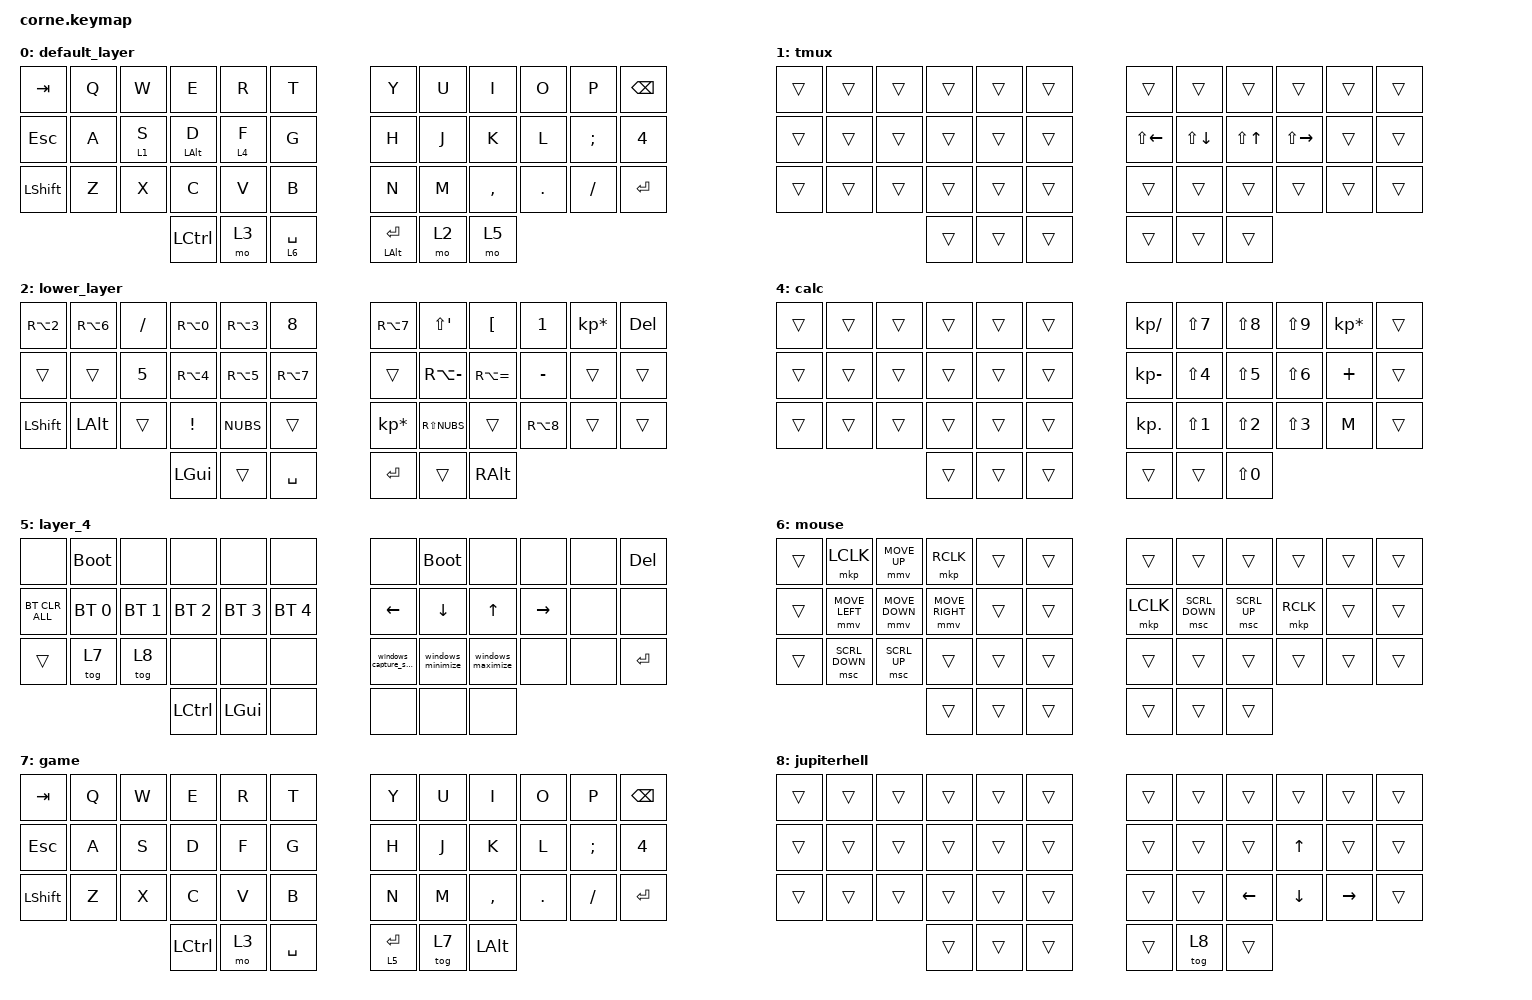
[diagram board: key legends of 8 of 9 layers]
/*
 * Copyright (c) 2020 The ZMK Contributors
 *
 * SPDX-License-Identifier: MIT
 */

#define ZMK_MOUSE_DEFAULT_MOVE_VAL 4000

#include <behaviors/mouse_keys.dtsi>
#include <dt-bindings/zmk/mouse.h>
#include <behaviors.dtsi>
#include <dt-bindings/zmk/bt.h>
#include <dt-bindings/zmk/keys.h>

#undef MOVE_UP
#undef MOVE_DOWN
#undef MOVE_LEFT
#undef MOVE_RIGHT

#define MOVE_UP MOVE_Y(-ZMK_MOUSE_DEFAULT_MOVE_VAL)
#define MOVE_DOWN MOVE_Y(ZMK_MOUSE_DEFAULT_MOVE_VAL)
#define MOVE_LEFT MOVE_X(-ZMK_MOUSE_DEFAULT_MOVE_VAL)
#define MOVE_RIGHT MOVE_X(ZMK_MOUSE_DEFAULT_MOVE_VAL)

&msc {
    time-to-max-speed-ms = <800>;             /* <--- How long time until max speed is reached (default: 500) */
};

/ {
    macros {
        macro_greater_than: macro_greater_than {
            compatible = "zmk,behavior-macro";
            #binding-cells = <0>;
            bindings =
                <&macro_press>,
                <&kp LEFT_ALT>,
                <&macro_tap>,
                <&kp KP_NUMBER_6 &kp KP_N2>,
                <&macro_release>,
                <&kp LEFT_ALT>;

            label = "MACRO_GREATER_THAN";
        };

        macro_less_than: macro_less_than {
            compatible = "zmk,behavior-macro";
            #binding-cells = <0>;
            bindings =
                <&macro_press>,
                <&kp LEFT_ALT>,
                <&macro_tap>,
                <&kp KP_NUMBER_6 &kp KP_N0>,
                <&macro_release>,
                <&kp LEFT_ALT>;

            label = "MACRO_LESS_THAN";
        };

        windows_capture_screen: windows_capture_screen {
            compatible = "zmk,behavior-macro";
            #binding-cells = <0>;
            bindings =
                <&macro_press>,
                <&kp LEFT_GUI>,
                <&macro_tap>,
                <&kp LS(S)>,
                <&macro_release>,
                <&kp LGUI>;

            label = "WINDOWS_CAPTURE_SCREEN";
        };

        windows_maximize: windows_fullscreen {
            compatible = "zmk,behavior-macro";
            #binding-cells = <0>;
            bindings =
                <&macro_press>,
                <&kp LEFT_GUI>,
                <&macro_tap>,
                <&kp UP_ARROW>,
                <&macro_release>,
                <&kp LGUI>;

            label = "WINDOWS_FULLSCREEN";
        };

        windows_minimize: windows_minimize {
            compatible = "zmk,behavior-macro";
            #binding-cells = <0>;
            bindings =
                <&macro_press>,
                <&kp LEFT_GUI>,
                <&macro_tap>,
                <&kp DOWN>,
                <&macro_release>,
                <&kp LEFT_GUI>;

            label = "WINDOWS_MINIMIZE";
        };
    };

    behaviors {
        homerow_alt: homerow_alt {
            compatible = "zmk,behavior-hold-tap";
            label = "HOMEROW_ALT";
            bindings = <&kp>, <&kp>;

            #binding-cells = <2>;
            flavor = "tap-preferred";
            tapping-term-ms = <170>;
            quick-tap-ms = <150>;
            require-prior-idle-ms = <0>;
            hold-trigger-key-positions = <14 15 16 19 20 21 22 18>;
        };

        mouse: mouse {
            compatible = "zmk,behavior-hold-tap";
            label = "MOUSE";
            bindings = <&mo>, <&kp>;

            #binding-cells = <2>;
            flavor = "tap-preferred";
            tapping-term-ms = <170>;
            quick-tap-ms = <150>;
            require-prior-idle-ms = <0>;
            hold-trigger-key-positions = <2 14 13 15 1 3>;
        };
    };

    keymap {
        compatible = "zmk,keymap";

        default_layer {
            // -----------------------------------------------------------------------------------------
            // |  TAB |  Q  |  W  |  E  |  R  |  T  |   |  Y  |  U   |  I  |  O  |  P  | BKSP |
            // | CTRL |  A  |  S  |  D  |  F  |  G  |   |  H  |  J   |  K  |  L  |  ;  |  '   |
            // | SHFT |  Z  |  X  |  C  |  V  |  B  |   |  N  |  M   |  ,  |  .  |  /  | ESC  |
            //                    | GUI | LWR | SPC |   | ENT | RSE  | ALT |

            bindings = <
&kp TAB     &kp Q  &kp W    &kp E                    &kp R    &kp T             &kp Y               &kp U  &kp I      &kp O    &kp P     &kp BSPC
&kp ESCAPE  &kp A  &lt 1 S  &homerow_alt LEFT_ALT D  &lt 4 F  &kp G             &kp H               &kp J  &kp K      &kp L    &kp SEMI  &kp NUMBER_4
&kp LSHFT   &kp Z  &kp X    &kp C                    &kp V    &kp B             &kp N               &kp M  &kp COMMA  &kp DOT  &kp FSLH  &kp ENTER
                            &kp LEFT_CONTROL         &mo 3    &mouse 6 SPACE    &mt LEFT_ALT ENTER  &mo 2  &mo 5
            >;
        };

        tmux {
            bindings = <
&trans  &trans  &trans  &trans  &trans  &trans    &trans        &trans        &trans            &trans         &trans  &trans
&trans  &trans  &trans  &trans  &trans  &trans    &kp LS(LEFT)  &kp LS(DOWN)  &kp LS(UP_ARROW)  &kp LS(RIGHT)  &trans  &trans
&trans  &trans  &trans  &trans  &trans  &trans    &trans        &trans        &trans            &trans         &trans  &trans
                        &trans  &trans  &trans    &trans        &trans        &trans
            >;
        };

        lower_layer {
            // -----------------------------------------------------------------------------------------
            // |  TAB |  1  |  2  |  3  |  4  |  5  |   |  6  |  7  |  8  |  9  |  0  | BKSP |
            // | BTCLR| BT1 | BT2 | BT3 | BT4 | BT5 |   | LFT | DWN |  UP | RGT |     |      |
            // | SHFT |     |     |     |     |     |   |     |     |     |     |     |      |
            //                    | GUI |     | SPC |   | ENT |     | ALT |

            bindings = <
&kp RA(NUMBER_2)  &kp RA(NUMBER_6)  &kp SLASH  &kp RA(N0)        &kp RA(NUMBER_3)  &kp N8        &kp RA(N7)       &kp LS(SQT)    &kp LEFT_BRACKET  &kp NUMBER_1  &kp KP_MULTIPLY  &kp DELETE
&trans            &trans            &kp N5     &kp RA(NUMBER_4)  &kp RA(N5)        &kp RA(N7)    &trans           &kp RA(MINUS)  &kp RA(EQUAL)     &kp MINUS     &trans           &trans
&kp LSHFT         &kp LEFT_ALT      &trans     &kp EXCLAMATION   &kp NUBS          &trans        &kp KP_MULTIPLY  &kp RS(NUBS)   &trans            &kp RA(N8)    &trans           &trans
                                               &kp LGUI          &trans            &kp SPACE     &kp RET          &trans         &kp RALT
            >;
        };

        raise_layer {
            // -----------------------------------------------------------------------------------------
            // |  TAB |  !  |  @  |  #  |  $  |  %  |   |  ^  |  &  |  *  |  (  |  )  | BKSP |
            // | CTRL |     |     |     |     |     |   |  -  |  =  |  [  |  ]  |  \  |  `   |
            // | SHFT |     |     |     |     |     |   |  _  |  +  |  {  |  }  | "|" |  ~   |
            //                    | GUI |     | SPC |   | ENT |     | ALT |

            bindings = <
&kp GRAVE  &kp NUMBER_1  &kp NUMBER_2  &kp NUMBER_3  &kp NUMBER_4  &kp N5     &kp NUMBER_6  &kp N7     &kp N8     &kp N9            &kp N0             &kp BSPC
&trans     &kp F1        &kp F2        &kp F3        &kp F4        &kp F5     &kp F6        &kp MINUS  &kp EQUAL  &kp LEFT_BRACKET  &kp RIGHT_BRACKET  &kp SQT
&trans     &kp F7        &kp F8        &kp F9        &kp F10       &kp F11    &kp F12       &kp NUHS   &kp NUBS   &trans            &trans             &kp TILDE
            >;
        };

        calc {
            bindings = <
&trans  &trans  &trans  &trans  &trans  &trans    &kp KP_DIVIDE  &kp LS(N7)        &kp LS(NUMBER_8)  &kp LS(N9)        &kp KP_ASTERISK  &trans
&trans  &trans  &trans  &trans  &trans  &trans    &kp KP_MINUS   &kp LS(NUMBER_4)  &kp LS(NUMBER_5)  &kp LS(NUMBER_6)  &kp PLUS         &trans
&trans  &trans  &trans  &trans  &trans  &trans    &kp KP_DOT     &kp LS(NUMBER_1)  &kp LS(NUMBER_2)  &kp LS(NUMBER_3)  &kp M            &trans
                        &trans  &trans  &trans    &trans         &trans            &kp LS(NUMBER_0)
            >;
        };

        layer_4 {
            bindings = <
&none           &bootloader   &none         &none         &none         &none           &none                    &bootloader        &none              &none      &none  &kp DELETE
&bt BT_CLR_ALL  &bt BT_SEL 0  &bt BT_SEL 1  &bt BT_SEL 2  &bt BT_SEL 3  &bt BT_SEL 4    &kp LEFT                 &kp DOWN_ARROW     &kp UP_ARROW       &kp RIGHT  &none  &none
&trans          &tog 7        &tog 8        &none         &none         &none           &windows_capture_screen  &windows_minimize  &windows_maximize  &none      &none  &kp ENTER
                                            &kp LCTRL     &kp LEFT_GUI  &none           &none                    &none              &none
            >;
        };

        mouse {
            bindings = <
&trans  &mkp LCLK       &mmv MOVE_UP    &mkp RCLK        &trans  &trans    &trans     &trans          &trans        &trans     &trans  &trans
&trans  &mmv MOVE_LEFT  &mmv MOVE_DOWN  &mmv MOVE_RIGHT  &trans  &trans    &mkp LCLK  &msc SCRL_DOWN  &msc SCRL_UP  &mkp RCLK  &trans  &trans
&trans  &msc SCRL_DOWN  &msc SCRL_UP    &trans           &trans  &trans    &trans     &trans          &trans        &trans     &trans  &trans
                                        &trans           &trans  &trans    &trans     &trans          &trans
            >;
        };

        game {
            bindings = <
&kp TAB         &kp Q  &kp W  &kp E             &kp R  &kp T        &kp Y        &kp U   &kp I         &kp O    &kp P     &kp BSPC
&kp ESCAPE      &kp A  &kp S  &kp D             &kp F  &kp G        &kp H        &kp J   &kp K         &kp L    &kp SEMI  &kp NUMBER_4
&kp LEFT_SHIFT  &kp Z  &kp X  &kp C             &kp V  &kp B        &kp N        &kp M   &kp COMMA     &kp DOT  &kp FSLH  &kp ENTER
                              &kp LEFT_CONTROL  &mo 3  &kp SPACE    &lt 5 ENTER  &tog 7  &kp LEFT_ALT
            >;
        };

        jupiterhell {
            bindings = <
&trans  &trans  &trans  &trans  &trans  &trans    &trans  &trans  &trans    &trans        &trans     &trans
&trans  &trans  &trans  &trans  &trans  &trans    &trans  &trans  &trans    &kp UP_ARROW  &trans     &trans
&trans  &trans  &trans  &trans  &trans  &trans    &trans  &trans  &kp LEFT  &kp DOWN      &kp RIGHT  &trans
                        &trans  &trans  &trans    &trans  &tog 8  &trans
            >;
        };
    };

    conditional_layers { compatible = "zmk,conditional-layers"; };
};
